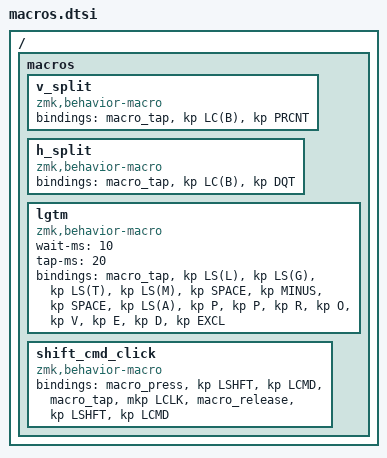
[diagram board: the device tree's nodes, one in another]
/ {
    macros {
        v_split: v_split {
            compatible = "zmk,behavior-macro";
            #binding-cells = <0>;
            bindings = <&macro_tap &kp LC(B) &kp PRCNT>;
        };

        h_split: h_split {
            compatible = "zmk,behavior-macro";
            #binding-cells = <0>;
            bindings = <&macro_tap &kp LC(B) &kp DQT>;
        };

        lgtm: lgtm { // LGTM Approval
            compatible = "zmk,behavior-macro";
            #binding-cells = <0>;
            wait-ms = <10>;
            tap-ms = <20>;
            bindings = <
                &macro_tap
                &kp LS(L) &kp LS(G) &kp LS(T) &kp LS(M)
                &kp SPACE &kp MINUS &kp SPACE
                &kp LS(A) &kp P &kp P &kp R &kp O &kp V &kp E &kp D &kp EXCL
            >;
        };

        shift_cmd_click: shift_cmd_click { // Shift+Cmd+Click (macOS: open in new tab)
            compatible = "zmk,behavior-macro";
            #binding-cells = <0>;
            bindings =
                <&macro_press &kp LSHFT &kp LCMD>,
                <&macro_tap &mkp LCLK>,
                <&macro_release &kp LSHFT &kp LCMD>;
        };
    };
};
